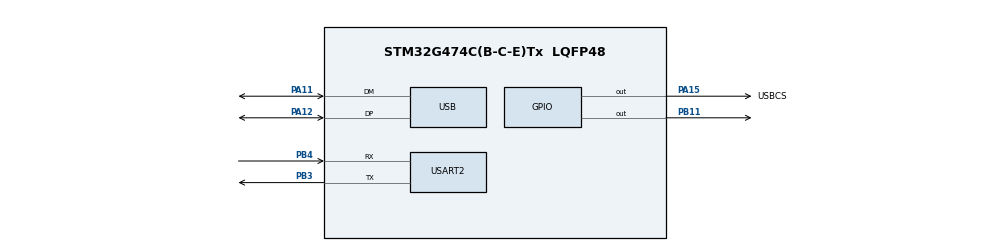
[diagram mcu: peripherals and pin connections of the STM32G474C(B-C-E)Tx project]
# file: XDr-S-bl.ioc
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Dma.Request0=USART2_RX
Dma.Request1=USART2_TX
Dma.USART2_RX.0.Direction=DMA_PERIPH_TO_MEMORY
Dma.USART2_RX.0.EventEnable=DISABLE
Dma.USART2_RX.0.Instance=DMA1_Channel2
Dma.USART2_RX.0.MemDataAlignment=DMA_MDATAALIGN_BYTE
Dma.USART2_RX.0.MemInc=DMA_MINC_ENABLE
Dma.USART2_RX.0.Mode=DMA_CIRCULAR
Dma.USART2_RX.0.PeriphDataAlignment=DMA_PDATAALIGN_BYTE
Dma.USART2_RX.0.PeriphInc=DMA_PINC_DISABLE
Dma.USART2_RX.0.Polarity=HAL_DMAMUX_REQ_GEN_RISING
Dma.USART2_RX.0.Priority=DMA_PRIORITY_LOW
Dma.USART2_RX.0.RequestNumber=1
Dma.USART2_RX.0.SignalID=NONE
Dma.USART2_RX.0.SyncEnable=DISABLE
Dma.USART2_RX.0.SyncPolarity=HAL_DMAMUX_SYNC_NO_EVENT
Dma.USART2_RX.0.SyncRequestNumber=1
Dma.USART2_RX.0.SyncSignalID=NONE
Dma.USART2_TX.1.Direction=DMA_MEMORY_TO_PERIPH
Dma.USART2_TX.1.EventEnable=DISABLE
Dma.USART2_TX.1.Instance=DMA1_Channel3
Dma.USART2_TX.1.MemDataAlignment=DMA_MDATAALIGN_BYTE
Dma.USART2_TX.1.MemInc=DMA_MINC_ENABLE
Dma.USART2_TX.1.Mode=DMA_NORMAL
Dma.USART2_TX.1.PeriphDataAlignment=DMA_PDATAALIGN_BYTE
Dma.USART2_TX.1.PeriphInc=DMA_PINC_DISABLE
Dma.USART2_TX.1.Polarity=HAL_DMAMUX_REQ_GEN_RISING
Dma.USART2_TX.1.Priority=DMA_PRIORITY_LOW
Dma.USART2_TX.1.RequestNumber=1
Dma.USART2_TX.1.SignalID=NONE
Dma.USART2_TX.1.SyncEnable=DISABLE
Dma.USART2_TX.1.SyncPolarity=HAL_DMAMUX_SYNC_NO_EVENT
Dma.USART2_TX.1.SyncRequestNumber=1
Dma.USART2_TX.1.SyncSignalID=NONE
Mcu.Family=STM32G4
Mcu.Name=STM32G474C(B-C-E)Tx
Mcu.Package=LQFP48
NVIC.DMA1_Channel2_IRQn=true\:2\:1\:true\:false\:true\:false\:true\:true
NVIC.DMA1_Channel3_IRQn=true\:2\:1\:true\:false\:true\:false\:true\:true
NVIC.PriorityGroup=NVIC_PRIORITYGROUP_2
NVIC.USART2_IRQn=true\:2\:2\:true\:false\:true\:true\:true\:true
NVIC.USB_LP_IRQn=true\:0\:0\:false\:false\:true\:false\:true\:true
PA11.Mode=Device
PA11.Signal=USB_DM
PA12.Mode=Device
PA12.Signal=USB_DP
PA13.Mode=Serial_Wire
PA13.Signal=SYS_JTMS-SWDIO
PA14.Mode=Serial_Wire
PA14.Signal=SYS_JTCK-SWCLK
PA15.GPIO_Label=USBCS
PA15.GPIO_Speed=GPIO_SPEED_FREQ_HIGH
PA15.Signal=GPIO_Output
PB11.Signal=GPIO_Output
PB3.Mode=Asynchronous
PB3.Signal=USART2_TX
PB4.Mode=Asynchronous
PB4.Signal=USART2_RX
PF0-OSC_IN.Mode=HSE-External-Oscillator
PF0-OSC_IN.Signal=RCC_OSC_IN
PF1-OSC_OUT.Mode=HSE-External-Oscillator
PF1-OSC_OUT.Signal=RCC_OSC_OUT
ProjectManager.HeapSize=0x800
ProjectManager.StackSize=0x1200
ProjectManager.TargetToolchain=CMake
RCC.ADC12Freq_Value=170000000
RCC.ADC345Freq_Value=170000000
RCC.AHBFreq_Value=170000000
RCC.APB1Freq_Value=170000000
RCC.APB1TimFreq_Value=170000000
RCC.APB2Freq_Value=170000000
RCC.APB2TimFreq_Value=170000000
RCC.CK48CLockSelection=RCC_USBCLKSOURCE_HSI48
RCC.CortexFreq_Value=170000000
RCC.EXTERNAL_CLOCK_VALUE=12288000
RCC.HCLKFreq_Value=170000000
RCC.HSE_VALUE=25000000
RCC.HSI48_VALUE=48000000
RCC.HSI_VALUE=16000000
RCC.LSE_VALUE=32768
RCC.PLLM=RCC_PLLM_DIV5
RCC.PLLN=68
RCC.PLLSourceVirtual=RCC_PLLSOURCE_HSE
RCC.SYSCLKFreq_VALUE=170000000
RCC.SYSCLKSource=RCC_SYSCLKSOURCE_PLLCLK
RCC.USBFreq_Value=48000000
RCC.VCOOutputFreq_Value=340000000
STMicroelectronics.X-CUBE-ALGOBUILD.1.5.0.LibraryCcDSPOoLibraryJjDSPOoLibrary=true
USART2.FIFOMode=FIFOMODE_ENABLE
USART2.RXFIFOThreshold=RXFIFO_THRESHOLD_1EIGHTHFULL
USART2.TXFIFOThreshold=TXFIFO_THRESHOLD_1EIGHTHFULL
USART2.VirtualMode-Asynchronous=VM_ASYNC
USB_DEVICE.CLASS_NAME_FS=CUSTOM_HID
USB_DEVICE.VirtualMode=CustomHid
USB_DEVICE.VirtualModeFS=Custom_Hid_FS
VP_STMicroelectronics.X-CUBE-ALGOBUILD_VS_DSPOoLibraryJjLibrary_1.5.0_1.5.0.Mode=DSPOoLibraryJjLibrary
VP_SYS_VS_DBSignals.Mode=DisableDeadBatterySignals
VP_USB_DEVICE_VS_USB_DEVICE_CUSTOM_HID_FS.Mode=CUSTOM_HID_FS
board=custom

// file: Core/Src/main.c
/* USER CODE BEGIN Header */
/**
 ******************************************************************************
 * @file           : main.c
 * @brief          : Main program body
 ******************************************************************************
 * @attention
 *
 * Copyright (c) 2026 STMicroelectronics.
 * All rights reserved.
 *
 * This software is licensed under terms that can be found in the LICENSE file
 * in the root directory of this software component.
 * If no LICENSE file comes with this software, it is provided AS-IS.
 *
 ******************************************************************************
 */
/* USER CODE END Header */
#include "main.h"
#include "dma.h"
#include "gpio.h"
#include "usart.h"
#include "usb_device.h"

/* USER CODE BEGIN Includes */
#include "bl_main.h"
#include "bsp_mcu.h"
/* USER CODE END Includes */

void SystemClock_Config(void);

int main(void) {

    /* MCU
     * Configuration--------------------------------------------------------*/

    /* Reset of all peripherals, Initializes the Flash interface and the
     * Systick. */
    HAL_Init();

    /* Configure the system clock */
    SystemClock_Config();

    /* Initialize all configured peripherals */
    MX_GPIO_Init();
    MX_DMA_Init();
    MX_USART2_UART_Init();
    MX_USB_Device_Init();
    /* USER CODE BEGIN 2 */
    if (!bsp_base_init())
        Error_Handler();
    if (!bl_main_init())
        Error_Handler();
    bl_main_start();
    /* USER CODE END 2 */

    /* Infinite loop */
    while (1) {

    }
}

void SystemClock_Config(void) {
    LL_FLASH_SetLatency(LL_FLASH_LATENCY_4);
    while (LL_FLASH_GetLatency() != LL_FLASH_LATENCY_4) {
    }
    LL_PWR_EnableRange1BoostMode();
    LL_RCC_HSE_Enable();
    /* Wait till HSE is ready */
    while (LL_RCC_HSE_IsReady() != 1) {
    }

    LL_RCC_HSI48_Enable();
    /* Wait till HSI48 is ready */
    while (LL_RCC_HSI48_IsReady() != 1) {
    }

    LL_RCC_PLL_ConfigDomain_SYS(
        LL_RCC_PLLSOURCE_HSE, LL_RCC_PLLM_DIV_5, 68, LL_RCC_PLLR_DIV_2);
    LL_RCC_PLL_EnableDomain_SYS();
    LL_RCC_PLL_Enable();
    /* Wait till PLL is ready */
    while (LL_RCC_PLL_IsReady() != 1) {
    }

    LL_RCC_SetSysClkSource(LL_RCC_SYS_CLKSOURCE_PLL);
    LL_RCC_SetAHBPrescaler(LL_RCC_SYSCLK_DIV_2);
    /* Wait till System clock is ready */
    while (LL_RCC_GetSysClkSource() != LL_RCC_SYS_CLKSOURCE_STATUS_PLL) {
    }

    /* Insure 1us transition state at intermediate medium speed clock*/
    for (__IO uint32_t i = (170 >> 1); i != 0; i--)
        ;

    /* Set AHB prescaler*/
    LL_RCC_SetAHBPrescaler(LL_RCC_SYSCLK_DIV_1);
    LL_RCC_SetAPB1Prescaler(LL_RCC_APB1_DIV_1);
    LL_RCC_SetAPB2Prescaler(LL_RCC_APB2_DIV_1);
    LL_SetSystemCoreClock(170000000);

    /* Update the time base */
    if (HAL_InitTick(TICK_INT_PRIORITY) != HAL_OK) {
        Error_Handler();
    }
}

void Error_Handler(void) {
    /* USER CODE BEGIN Error_Handler_Debug */
    /* User can add his own implementation to report the HAL error return state
     */
    __disable_irq();
    while (1) {
    }
    /* USER CODE END Error_Handler_Debug */
}
#ifdef USE_FULL_ASSERT
/**
 * @brief  Reports the name of the source file and the source line number
 *         where the assert_param error has occurred.
 * @param  file: pointer to the source file name
 * @param  line: assert_param error line source number
 * @retval None
 */
void assert_failed(uint8_t *file, uint32_t line) {
    /* USER CODE BEGIN 6 */
    /* User can add his own implementation to report the file name and line
       number, ex: printf("Wrong parameters value: file %s on line %d\r\n",
       file, line) */
    /* USER CODE END 6 */
}
#endif /* USE_FULL_ASSERT */
